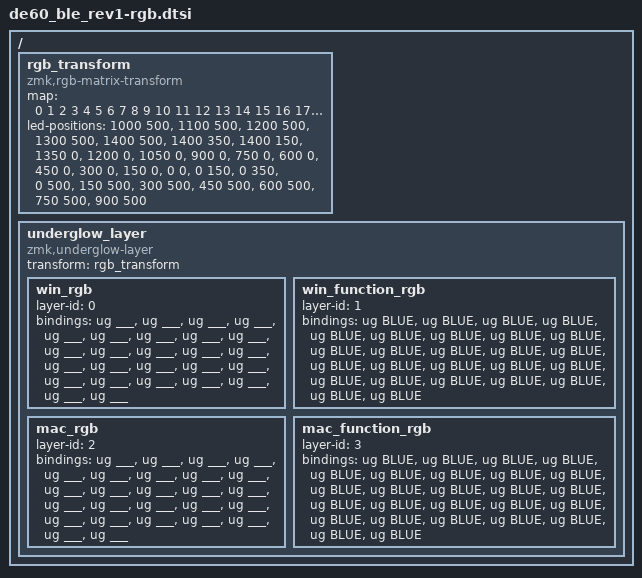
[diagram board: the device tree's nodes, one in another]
/*
 * Copyright (c) 2025 Team PHDesign
 *
 * SPDX-License-Identifier: MIT
 */

#include <dt-bindings/zmk/rgb.h>
#include <dt-bindings/zmk/rgb_colors.h>

/ {
    rgb_transform: rgb_transform {
        compatible = "zmk,rgb-matrix-transform";

        // map[strip_idx] = binding_idx
        // 数组长度 = chain-length (61)
        map = <
            // 16  15  14  13 12 11 10  9 8 7  // 10
            // 17                           6  // 2
            // 18                           5  // 2      
            // 19 20 21 22 23 24 25 0 1 2 3 4  // 12

            0 1 2 3 4 5 6 7 8 9 
            10 11
            12 13 
            14 15 16 17 18 19 20 21 22 23 24 25
        >;

        //        x     y
        led-positions
            = <1000   500>  // LED  0
            , <1100   500>  // LED  1
            , <1200   500>  // LED  2
            , <1300   500>  // LED  3
            , <1400   500>  // LED  4

            , <1400   350>  // LED  5
            , <1400   150>  // LED  6

            , <1350     0>  // LED  7
            , <1200     0>  // LED  8
            , <1050     0>  // LED  9
            , < 900     0>  // LED 10
            , < 750     0>  // LED 11
            , < 600     0>  // LED 12
            , < 450     0>  // LED 13
            , < 300     0>  // LED 14
            , < 150     0>  // LED 15
            , <   0     0>  // LED 16

            , <   0   150>  // LED 17
            , <   0   350>  // LED 18

            , <   0   500>  // LED 19
            , < 150   500>  // LED 20
            , < 300   500>  // LED 21
            , < 450   500>  // LED 22
            , < 600   500>  // LED 23
            , < 750   500>  // LED 24
            , < 900   500>  // LED 25
            ;
    };

    
    underglow_layer: underglow_layer {
        compatible = "zmk,underglow-layer";
        transform = <&rgb_transform>;

        win_rgb {
            layer-id = <0>;

            bindings = <
                &ug ___ &ug ___ &ug ___ &ug ___ &ug ___ &ug ___ &ug ___ &ug ___ &ug ___ &ug ___ 
                &ug ___ &ug ___
                &ug ___ &ug ___ 
                &ug ___ &ug ___ &ug ___ &ug ___ &ug ___ &ug ___ &ug ___ &ug ___ &ug ___ &ug ___ &ug ___ &ug ___
            >;
        };

        win_function_rgb {
            layer-id = <1>;

            bindings = <
                &ug BLUE &ug BLUE &ug BLUE &ug BLUE &ug BLUE &ug BLUE &ug BLUE &ug BLUE &ug BLUE &ug BLUE
                &ug BLUE &ug BLUE
                &ug BLUE &ug BLUE
                &ug BLUE &ug BLUE &ug BLUE &ug BLUE &ug BLUE &ug BLUE &ug BLUE &ug BLUE &ug BLUE &ug BLUE &ug BLUE &ug BLUE
            >;
        };

        mac_rgb {
            layer-id = <2>;

            bindings = <
                &ug ___ &ug ___ &ug ___ &ug ___ &ug ___ &ug ___ &ug ___ &ug ___ &ug ___ &ug ___ 
                &ug ___ &ug ___
                &ug ___ &ug ___ 
                &ug ___ &ug ___ &ug ___ &ug ___ &ug ___ &ug ___ &ug ___ &ug ___ &ug ___ &ug ___ &ug ___ &ug ___
            >;
        };

        mac_function_rgb {
            layer-id = <3>;

            bindings = <
                &ug BLUE &ug BLUE &ug BLUE &ug BLUE &ug BLUE &ug BLUE &ug BLUE &ug BLUE &ug BLUE &ug BLUE
                &ug BLUE &ug BLUE
                &ug BLUE &ug BLUE
                &ug BLUE &ug BLUE &ug BLUE &ug BLUE &ug BLUE &ug BLUE &ug BLUE &ug BLUE &ug BLUE &ug BLUE &ug BLUE &ug BLUE
            >;
        };

    };

};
